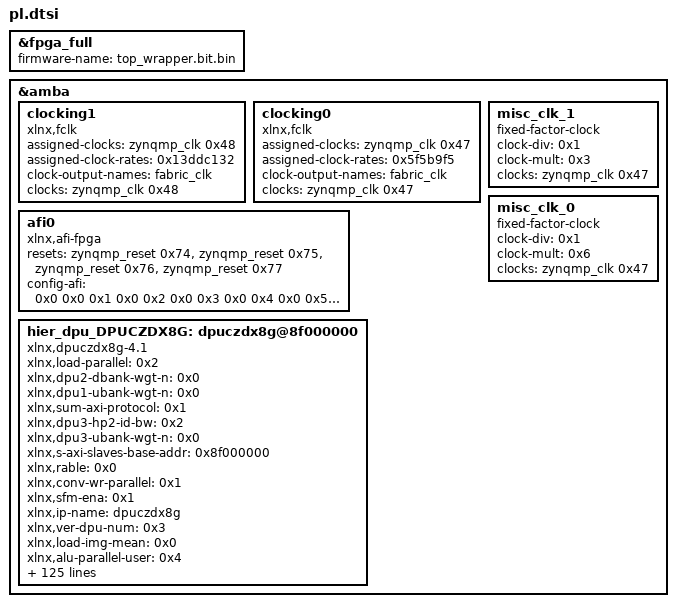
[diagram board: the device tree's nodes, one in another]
/dts-v1/;
/plugin/;
&fpga_full{
	firmware-name = "top_wrapper.bit.bin";
};
&amba{
	clocking1: clocking1 {
		compatible = "xlnx,fclk";
		status = "okay";
		assigned-clocks = <&zynqmp_clk 0x48>;
		assigned-clock-rates = <0x13ddc132>;
		#clock-cells = <0x0>;
		clock-output-names = "fabric_clk";
		clocks = <&zynqmp_clk 0x48>;
	};
	clocking0: clocking0 {
		compatible = "xlnx,fclk";
		status = "okay";
		assigned-clocks = <&zynqmp_clk 0x47>;
		assigned-clock-rates = <0x5f5b9f5>;
		#clock-cells = <0x0>;
		clock-output-names = "fabric_clk";
		clocks = <&zynqmp_clk 0x47>;
	};
	afi0: afi0 {
		status = "okay";
		compatible = "xlnx,afi-fpga";
		resets = <&zynqmp_reset 0x74>,
<&zynqmp_reset 0x75>,
<&zynqmp_reset 0x76>,
<&zynqmp_reset 0x77>;
		config-afi = <0x0 0x0 0x1 0x0 0x2 0x0 0x3 0x0 0x4 0x0 0x5 0x0 0x6 0x0 0x7 0x0 0x8 0x0 0x9 0x0 0xa 0x0 0xb 0x0 0xc 0x2 0xd 0x2 0xe 0xa00 0xf 0x0>;
	};
};
&amba{
	misc_clk_1: misc_clk_1 {
		clock-div = <0x1>;
		compatible = "fixed-factor-clock";
		clock-mult = <0x3>;
		clocks = <&zynqmp_clk 0x47>;
		#clock-cells = <0x0>;
	};
	misc_clk_0: misc_clk_0 {
		clock-div = <0x1>;
		compatible = "fixed-factor-clock";
		clock-mult = <0x6>;
		clocks = <&zynqmp_clk 0x47>;
		#clock-cells = <0x0>;
	};
	hier_dpu_DPUCZDX8G: dpuczdx8g@8f000000 {
		xlnx,load-parallel = <0x2>;
		xlnx,dpu2-dbank-wgt-n = <0x0>;
		xlnx,dpu1-ubank-wgt-n = <0x0>;
		xlnx,sum-axi-protocol = <0x1>;
		xlnx,dpu3-hp2-id-bw = <0x2>;
		xlnx,dpu3-ubank-wgt-n = <0x0>;
		xlnx,s-axi-slaves-base-addr = <0x8f000000>;
		xlnx,rable = <0x0>;
		xlnx,conv-wr-parallel = <0x1>;
		xlnx,sfm-ena = <0x1>;
		xlnx,ip-name = "dpuczdx8g";
		xlnx,ver-dpu-num = <0x3>;
		xlnx,load-img-mean = <0x0>;
		xlnx,alu-parallel-user = <0x4>;
		reg = <0x0 0x8f000000 0x0 0x1000000>;
		xlnx,bank-bias = <0x1>;
		xlnx,sum-s-axi-data-bw = <0x20>;
		xlnx,hp1-id-bw = <0x2>;
		xlnx,dnndk-print = "Number , of , DPU , Cores:3;Arch , of , DPU:B4096;RAM , Usage:Low;Channel , Augmentation:Enabled;DepthWiseConv:Enabled;AveragePool:Enabled;Conv , ReLU , Type:ReLU , + , LeakyReLU , + , ReLU6;Number , of , SFM , cores:1;S-AXI , Clock , Mode:Independent;dpu_2x , Clock , Gating:Enabled;DSP48 , Maximal , Cascade , Length:4;DSP48 , Usage:High;Ultra-RAM , Use , per , DPU:0;Enable , timestamp , auto-update:Enabled;Target , Version:1.4.1;AXI , Protocol:AXI4;S-AXI , Data , Width:32;M-AXI , GP , Data , Width:32;M-AXI , HP , Data , Width , (DPU):128;M-AXI , HP , Data , Width , (SFM):128;M-AXI , ID , Width:2;DSP , Slice , Count:2144;Ultra-RAM , Count:0.0;Block-RAM , Count:769.0";
		xlnx,time-day = <0x9>;
		xlnx,sum-sfm-hp-data-bw = <0x80>;
		xlnx,dbank-wgt-n = <0x0>;
		xlnx,uram-n-user = <0x0>;
		xlnx,ram-depth-img = <0x3>;
		xlnx,dpu1-dbank-img-n = <0x0>;
		xlnx,dpu3-dbank-bias = <0x0>;
		xlnx,dpu2-ubank-bias = <0x0>;
		xlnx,sum-gp-data-bw = <0x20>;
		xlnx,dpu3-dbank-img-n = <0x0>;
		xlnx,dpu2-ubank-img-n = <0x0>;
		xlnx,sys-ip-ver = <0x41>;
		interrupt-names = "dpu0_interrupt", "dpu1_interrupt", "dpu2_interrupt", "sfm_interrupt";
		xlnx,dpu2-hp0-id-bw = <0x2>;
		xlnx,ram-depth-wgt = <0x3>;
		xlnx,ubank-img-n-user = <0x0>;
		xlnx,time-month = <0x5>;
		xlnx,dpu3-hp1-id-bw = <0x2>;
		compatible = "xlnx,dpuczdx8g-4.1";
		xlnx,dpu1-hp3-id-bw = <0x2>;
		xlnx,sum-ver-target = "1.4.1";
		xlnx,bbank-img-n = <0x10>;
		xlnx,git-commit-id = <0x7d32c41>;
		xlnx,conv-dsp-casc-max = <0x4>;
		xlnx,ubank-bias = <0x0>;
		xlnx,arch-ocp = <0x10>;
		interrupt-parent = <&gic>;
		xlnx,ubank-img-n = <0x0>;
		xlnx,git-commit-time = <0x7894de29>;
		xlnx,sum-hp-data-bw = <0x80>;
		xlnx,sum-bram-n = <0x301>;
		xlnx,conv-dsp-num = <0x280>;
		xlnx,hp0-id-bw = <0x2>;
		xlnx,arch-hp-bw = <0x3>;
		xlnx,conv-relu6 = <0x1>;
		xlnx,ver-chip-part = <0x3>;
		xlnx,s-axi-id-bw = <0x10>;
		xlnx,dpu1-dbank-bias = <0x0>;
		xlnx,elew-mult-en = <0x1>;
		xlnx,alu-parallel = <0x4>;
		xlnx,conv-dsp-accu-ena = <0x1>;
		xlnx,ver-ip-rev = <0x0>;
		xlnx,dsp48-ver = "DSP48E2";
		xlnx,alu-leakyrelu = <0x0>;
		xlnx,git-commit-user = "jasonjia";
		status = "okay";
		xlnx,sys-regmap-size = <0xc>;
		xlnx,dpu3-hp0-id-bw = <0x2>;
		xlnx,name = "hier_dpu_DPUCZDX8G";
		xlnx,bank-img-n = <0x10>;
		xlnx,dpu1-dbank-wgt-n = <0x0>;
		xlnx,dpu1-hp2-id-bw = <0x2>;
		interrupts = <0x0 0x59 0x4 0x0 0x5a 0x4 0x0 0x5b 0x4 0x0 0x5c 0x4>;
		xlnx,sum-uram-n = <0x0>;
		xlnx,dpu3-dbank-wgt-n = <0x0>;
		xlnx,dpu2-ubank-wgt-n = <0x0>;
		xlnx,dpu2-hp3-id-bw = <0x2>;
		xlnx,arch-pp = <0x8>;
		xlnx,save-argmax-ena = <0x1>;
		xlnx,ram-depth-bias = <0x3>;
		xlnx,dpu3-ubank-bias = <0x0>;
		xlnx,arch = <0x1000>;
		xlnx,sfm-hp-data-bw = <0x80>;
		xlnx,bbank-wgt-n = <0x11>;
		clocks = <&misc_clk_0>,
<&misc_clk_0>,
<&misc_clk_0>,
<&misc_clk_1>,
<&zynqmp_clk 0x47>;
		xlnx,ubank-bias-user = <0x0>;
		xlnx,s-axi-freq-mhz = <0x64>;
		xlnx,time-hour = <0xf>;
		xlnx,bbank-bias = <0x1>;
		xlnx,ubank-wgt-n = <0x0>;
		xlnx,hp3-id-bw = <0x2>;
		xlnx,arch-data-bw = <0x1>;
		xlnx,sys-ip-type = <0x1>;
		xlnx,edk-iptype = "PERIPHERAL";
		xlnx,dwcv-ena = <0x1>;
		xlnx,dpu1-ubank-img-n = <0x0>;
		xlnx,dpu2-dbank-img-n = <0x0>;
		xlnx,s-axi-awrlen-bw = <0x8>;
		xlnx,dpu1-gp-id-bw = <0x2>;
		clock-names = "dpu1_2x_clk", "dpu2_2x_clk", "dpu_2x_clk", "m_axi_dpu_aclk", "s_axi_aclk";
		xlnx,ubank-wgt-n-user = <0x0>;
		xlnx,sfm-dsp-num = <0xe>;
		xlnx,dpu3-ubank-img-n = <0x0>;
		xlnx,arch-icp = <0x10>;
		xlnx,save-dsp-num = <0x1>;
		xlnx,ram-depth-mean = <0x1>;
		xlnx,dpu1-hp1-id-bw = <0x2>;
		xlnx,ver-target = <0x141>;
		xlnx,load-dsp-num = <0x1>;
		xlnx,pool-average = <0x1>;
		xlnx,dpu2-hp2-id-bw = <0x2>;
		xlnx,sfm-hp0-id-bw = <0x2>;
		xlnx,arch-img-bkgrp = <0x2>;
		xlnx,s-axi-clk-independent = <0x1>;
		xlnx,misc-wr-parallel = <0x1>;
		xlnx,dpu3-hp3-id-bw = <0x2>;
		xlnx,dpu1-ubank-bias = <0x0>;
		xlnx,dpu2-dbank-bias = <0x0>;
		xlnx,time-year = <0x19>;
		xlnx,hp-data-bw = <0x80>;
		xlnx,dbank-img-n = <0x0>;
		xlnx,sum-dsp-num = <0x860>;
		xlnx,bank-wgt-n = <0x11>;
		xlnx,load-augm = <0x1>;
		xlnx,dpu2-gp-id-bw = <0x2>;
		xlnx,time-quarter = <0x2>;
		xlnx,save-parallel = <0x2>;
		xlnx,conv-leakyrelu = <0x1>;
		xlnx,sys-regmap-ver = <0x1>;
		xlnx,hp2-id-bw = <0x2>;
		xlnx,clk-gating-ena = <0x1>;
		xlnx,alu-dsp-num = <0x44>;
		xlnx,dbank-bias = <0x0>;
		xlnx,timestamp-ena = <0x1>;
		xlnx,conv-relu-addon = <0x3>;
		xlnx,gp-id-bw = <0x2>;
		xlnx,elew-parallel = <0x4>;
		xlnx,dpu1-hp0-id-bw = <0x2>;
		xlnx,dpu3-gp-id-bw = <0x2>;
		xlnx,dpu2-hp1-id-bw = <0x2>;
		xlnx,axi-protocol = <0x1>;
	};
};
